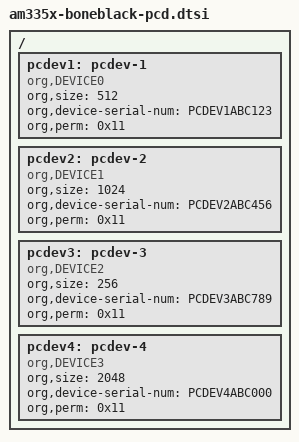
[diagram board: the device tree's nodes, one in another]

/ {
	pcdev1: pcdev-1 {
		compatible = "org,DEVICE0";
		org,size = <512>;
		org,device-serial-num = "PCDEV1ABC123";
		org,perm = <0x11>;
	};
	
	pcdev2: pcdev-2 {
		compatible = "org,DEVICE1";
		org,size = <1024>;
		org,device-serial-num = "PCDEV2ABC456";
		org,perm = <0x11>;
	};

	pcdev3: pcdev-3 {
		compatible = "org,DEVICE2";
		org,size = <256>;
		org,device-serial-num = "PCDEV3ABC789";
		org,perm = <0x11>;
	};
	
	pcdev4: pcdev-4 {
		compatible = "org,DEVICE3";
		org,size = <2048>;
		org,device-serial-num = "PCDEV4ABC000";
		org,perm = <0x11>;
	};

};


